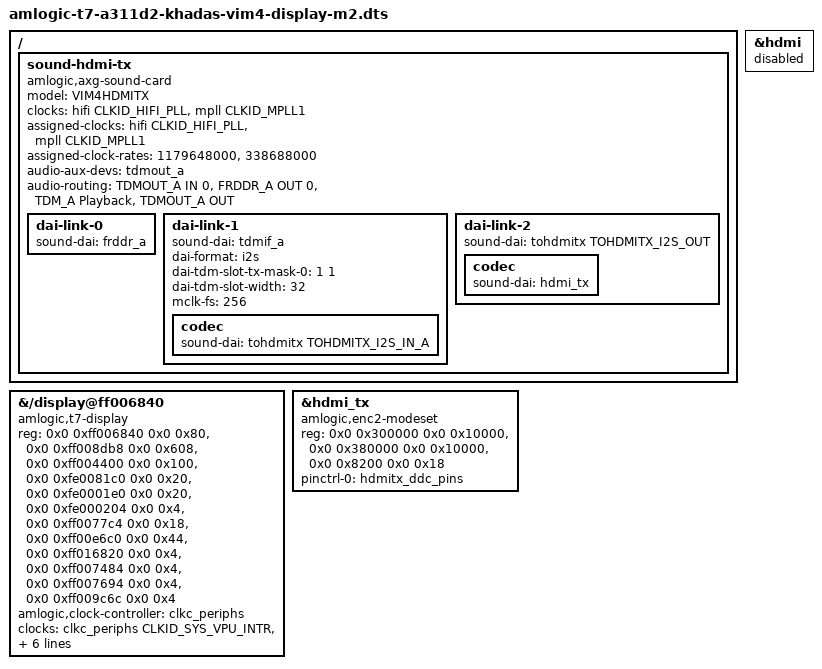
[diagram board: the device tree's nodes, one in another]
// SPDX-License-Identifier: (GPL-2.0+ OR MIT)
/* Experimental ENC2 modesetting with split capture/display resources. */
#include "amlogic-t7-a311d2-khadas-vim4-display-m1.dts"

&{/display@ff006840} {
	compatible = "amlogic,t7-display";
	reg = <0x0 0xff006840 0x0 0x80>,
	      <0x0 0xff008db8 0x0 0x608>,
	      <0x0 0xff004400 0x0 0x100>,
	      <0x0 0xfe0081c0 0x0 0x20>,
	      <0x0 0xfe0001e0 0x0 0x20>,
	      <0x0 0xfe000204 0x0 0x4>,
	      <0x0 0xff0077c4 0x0 0x18>,
	      <0x0 0xff00e6c0 0x0 0x44>,
	      <0x0 0xff016820 0x0 0x4>,
	      <0x0 0xff007484 0x0 0x4>,
	      <0x0 0xff007694 0x0 0x4>,
	      <0x0 0xff009c6c 0x0 0x4>;
	reg-names = "osd1", "venc", "rdma", "pll", "vid2", "vid-div",
		    "vpp", "blend", "scaler", "post-size", "out-size", "hdmi-setting";
	amlogic,clock-controller = <&clkc_periphs>;
	clocks = <&clkc_periphs CLKID_SYS_VPU_INTR>,
		 <&clkc_periphs CLKID_VPU>, <&clkc_periphs CLKID_VAPB>,
		 <&clkc_periphs CLKID_SYS_HDMITX_APB>, <&scmi_clk CLKID_HDMI_PLL_OSC>;
	interrupts = <GIC_SPI 197 IRQ_TYPE_EDGE_RISING>,
		     <GIC_SPI 215 IRQ_TYPE_EDGE_RISING>;
};

&hdmi_tx {
	/delete-property/ amlogic,boot-handoff;
	amlogic,enc2-modeset;
	reg = <0x0 0x300000 0x0 0x10000>,
	      <0x0 0x380000 0x0 0x10000>,
	      <0x0 0x8200 0x0 0x18>;
	reg-names = "top", "cor", "phy";
	#sound-dai-cells = <0>;
	pinctrl-0 = <&hdmitx_ddc_pins>;
	pinctrl-names = "default";
};

&hdmi {
	/* The native display owns all HDMI PLL registers, including OD fields. */
	status = "disabled";
};

/ {
	sound-hdmi-tx {
		compatible = "amlogic,axg-sound-card";
		model = "VIM4HDMITX";
		/* Vendor board's 48k/44.1k master families; RX uses its own ACR/PLL. */
		clocks = <&hifi CLKID_HIFI_PLL>, <&mpll CLKID_MPLL1>;
		assigned-clocks = <&hifi CLKID_HIFI_PLL>, <&mpll CLKID_MPLL1>;
		assigned-clock-rates = <1179648000>, <338688000>;
		audio-aux-devs = <&tdmout_a>;
		audio-routing = "TDMOUT_A IN 0", "FRDDR_A OUT 0",
				"TDM_A Playback", "TDMOUT_A OUT";

		dai-link-0 {
			sound-dai = <&frddr_a>;
		};

		dai-link-1 {
			sound-dai = <&tdmif_a>;
			dai-format = "i2s";
			dai-tdm-slot-tx-mask-0 = <1 1>;
			dai-tdm-slot-width = <32>;
			mclk-fs = <256>;
			codec {
				sound-dai = <&tohdmitx TOHDMITX_I2S_IN_A>;
			};
		};

		dai-link-2 {
			sound-dai = <&tohdmitx TOHDMITX_I2S_OUT>;
			codec {
				sound-dai = <&hdmi_tx>;
			};
		};
	};
};
